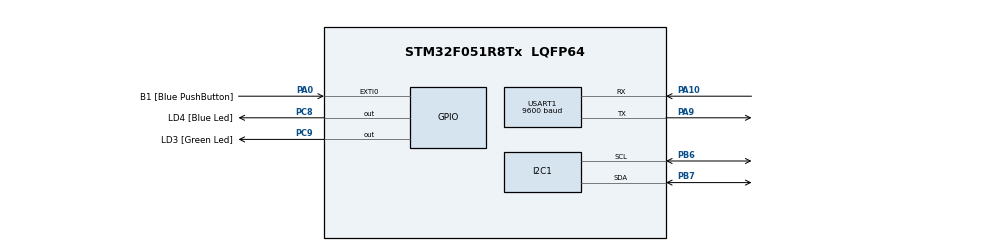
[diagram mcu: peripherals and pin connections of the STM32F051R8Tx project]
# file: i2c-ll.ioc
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I2C1.Timing=0x00201D2B
Mcu.Family=STM32F0
Mcu.Name=STM32F051R8Tx
Mcu.Package=LQFP64
PA0.GPIO_Label=B1 [Blue PushButton]
PA0.GPIO_ModeDefaultEXTI=GPIO_MODE_EVT_RISING
PA0.Signal=GPXTI0
PA10.Mode=Asynchronous
PA10.Signal=USART1_RX
PA13.GPIO_Label=SWDIO
PA13.Mode=Serial_Wire
PA13.Signal=SYS_SWDIO
PA14.GPIO_Label=SWCLK
PA14.Mode=Serial_Wire
PA14.Signal=SYS_SWCLK
PA9.Mode=Asynchronous
PA9.Signal=USART1_TX
PB6.Mode=I2C
PB6.Signal=I2C1_SCL
PB7.Mode=I2C
PB7.Signal=I2C1_SDA
PC8.GPIO_Label=LD4 [Blue Led]
PC8.Signal=GPIO_Output
PC9.GPIO_Label=LD3 [Green Led]
PC9.Signal=GPIO_Output
ProjectManager.HeapSize=0x200
ProjectManager.StackSize=0x400
ProjectManager.TargetToolchain=Makefile
RCC.AHBFreq_Value=48000000
RCC.APB1Freq_Value=48000000
RCC.APB1TimFreq_Value=48000000
RCC.HCLKFreq_Value=48000000
RCC.PLLMUL=RCC_PLL_MUL12
RCC.SYSCLKFreq_VALUE=48000000
RCC.SYSCLKSource=RCC_SYSCLKSOURCE_PLLCLK
USART1.BaudRate=9600
USART1.VirtualMode-Asynchronous=VM_ASYNC
board=STM32F0DISCOVERY

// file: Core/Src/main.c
/* USER CODE BEGIN Header */
/**
  ******************************************************************************
  * @file           : main.c
  * @brief          : Main program body
  ******************************************************************************
  * @attention
  *
  * Copyright (c) 2026 STMicroelectronics.
  * All rights reserved.
  *
  * This software is licensed under terms that can be found in the LICENSE file
  * in the root directory of this software component.
  * If no LICENSE file comes with this software, it is provided AS-IS.
  *
  ******************************************************************************
  */
/* USER CODE END Header */
#include "main.h"

/* USER CODE BEGIN Includes */
#include "bmp180_port.h"

/* USER CODE END Includes */

/* USER CODE BEGIN PV */
struct bmp180_t bmp180sensor;

/* USER CODE END PV */

void SystemClock_Config(void);
static void MX_GPIO_Init(void);
static void MX_I2C1_Init(void);
static void MX_USART1_UART_Init(void);

int main(void)
{

  /* MCU Configuration--------------------------------------------------------*/

  /* Reset of all peripherals, Initializes the Flash interface and the Systick. */
  LL_APB1_GRP2_EnableClock(LL_APB1_GRP2_PERIPH_SYSCFG);
  LL_APB1_GRP1_EnableClock(LL_APB1_GRP1_PERIPH_PWR);

  /* Configure the system clock */
  SystemClock_Config();

  /* Initialize all configured peripherals */
  MX_GPIO_Init();
  MX_I2C1_Init();
  MX_USART1_UART_Init();
  /* USER CODE BEGIN 2 */
  if (BMP180_PortInit(&bmp180sensor) != 0)
  {
    // init failed — check wiring/pull-ups/address
    while (1) { }
  }

  /* USER CODE END 2 */

  /* Infinite loop */
  while (1)
  {

  }
}

void SystemClock_Config(void)
{
  LL_FLASH_SetLatency(LL_FLASH_LATENCY_1);
  while(LL_FLASH_GetLatency() != LL_FLASH_LATENCY_1)
  {
  }
  LL_RCC_HSI_Enable();

   /* Wait till HSI is ready */
  while(LL_RCC_HSI_IsReady() != 1)
  {

  }
  LL_RCC_HSI_SetCalibTrimming(16);
  LL_RCC_PLL_ConfigDomain_SYS(LL_RCC_PLLSOURCE_HSI_DIV_2, LL_RCC_PLL_MUL_12);
  LL_RCC_PLL_Enable();

   /* Wait till PLL is ready */
  while(LL_RCC_PLL_IsReady() != 1)
  {

  }
  LL_RCC_SetAHBPrescaler(LL_RCC_SYSCLK_DIV_1);
  LL_RCC_SetAPB1Prescaler(LL_RCC_APB1_DIV_1);
  LL_RCC_SetSysClkSource(LL_RCC_SYS_CLKSOURCE_PLL);

   /* Wait till System clock is ready */
  while(LL_RCC_GetSysClkSource() != LL_RCC_SYS_CLKSOURCE_STATUS_PLL)
  {

  }
  LL_Init1msTick(48000000);
  LL_SetSystemCoreClock(48000000);
  LL_RCC_SetUSARTClockSource(LL_RCC_USART1_CLKSOURCE_PCLK1);
  LL_RCC_SetI2CClockSource(LL_RCC_I2C1_CLKSOURCE_HSI);
}

static void MX_I2C1_Init(void)
{

  LL_I2C_InitTypeDef I2C_InitStruct = {0};

  LL_GPIO_InitTypeDef GPIO_InitStruct = {0};

  LL_AHB1_GRP1_EnableClock(LL_AHB1_GRP1_PERIPH_GPIOB);
  /**I2C1 GPIO Configuration
  PB6   ------> I2C1_SCL
  PB7   ------> I2C1_SDA
  */
  GPIO_InitStruct.Pin = LL_GPIO_PIN_6;
  GPIO_InitStruct.Mode = LL_GPIO_MODE_ALTERNATE;
  GPIO_InitStruct.Speed = LL_GPIO_SPEED_FREQ_HIGH;
  GPIO_InitStruct.OutputType = LL_GPIO_OUTPUT_OPENDRAIN;
  GPIO_InitStruct.Pull = LL_GPIO_PULL_NO;
  GPIO_InitStruct.Alternate = LL_GPIO_AF_1;
  LL_GPIO_Init(GPIOB, &GPIO_InitStruct);

  GPIO_InitStruct.Pin = LL_GPIO_PIN_7;
  GPIO_InitStruct.Mode = LL_GPIO_MODE_ALTERNATE;
  GPIO_InitStruct.Speed = LL_GPIO_SPEED_FREQ_HIGH;
  GPIO_InitStruct.OutputType = LL_GPIO_OUTPUT_OPENDRAIN;
  GPIO_InitStruct.Pull = LL_GPIO_PULL_NO;
  GPIO_InitStruct.Alternate = LL_GPIO_AF_1;
  LL_GPIO_Init(GPIOB, &GPIO_InitStruct);

  /* Peripheral clock enable */
  LL_APB1_GRP1_EnableClock(LL_APB1_GRP1_PERIPH_I2C1);

  /** I2C Initialization
  */
  LL_I2C_DisableOwnAddress2(I2C1);
  LL_I2C_DisableGeneralCall(I2C1);
  LL_I2C_EnableClockStretching(I2C1);
  I2C_InitStruct.PeripheralMode = LL_I2C_MODE_I2C;
  I2C_InitStruct.Timing = 0x00201D2B;
  I2C_InitStruct.AnalogFilter = LL_I2C_ANALOGFILTER_ENABLE;
  I2C_InitStruct.DigitalFilter = 0;
  I2C_InitStruct.OwnAddress1 = 0;
  I2C_InitStruct.TypeAcknowledge = LL_I2C_ACK;
  I2C_InitStruct.OwnAddrSize = LL_I2C_OWNADDRESS1_7BIT;
  LL_I2C_Init(I2C1, &I2C_InitStruct);
  LL_I2C_EnableAutoEndMode(I2C1);
  LL_I2C_SetOwnAddress2(I2C1, 0, LL_I2C_OWNADDRESS2_NOMASK);

}

static void MX_USART1_UART_Init(void)
{

  LL_USART_InitTypeDef USART_InitStruct = {0};

  LL_GPIO_InitTypeDef GPIO_InitStruct = {0};

  /* Peripheral clock enable */
  LL_APB1_GRP2_EnableClock(LL_APB1_GRP2_PERIPH_USART1);

  LL_AHB1_GRP1_EnableClock(LL_AHB1_GRP1_PERIPH_GPIOA);
  /**USART1 GPIO Configuration
  PA9   ------> USART1_TX
  PA10   ------> USART1_RX
  */
  GPIO_InitStruct.Pin = LL_GPIO_PIN_9;
  GPIO_InitStruct.Mode = LL_GPIO_MODE_ALTERNATE;
  GPIO_InitStruct.Speed = LL_GPIO_SPEED_FREQ_HIGH;
  GPIO_InitStruct.OutputType = LL_GPIO_OUTPUT_PUSHPULL;
  GPIO_InitStruct.Pull = LL_GPIO_PULL_NO;
  GPIO_InitStruct.Alternate = LL_GPIO_AF_1;
  LL_GPIO_Init(GPIOA, &GPIO_InitStruct);

  GPIO_InitStruct.Pin = LL_GPIO_PIN_10;
  GPIO_InitStruct.Mode = LL_GPIO_MODE_ALTERNATE;
  GPIO_InitStruct.Speed = LL_GPIO_SPEED_FREQ_HIGH;
  GPIO_InitStruct.OutputType = LL_GPIO_OUTPUT_PUSHPULL;
  GPIO_InitStruct.Pull = LL_GPIO_PULL_NO;
  GPIO_InitStruct.Alternate = LL_GPIO_AF_1;
  LL_GPIO_Init(GPIOA, &GPIO_InitStruct);

  USART_InitStruct.BaudRate = 9600;
  USART_InitStruct.DataWidth = LL_USART_DATAWIDTH_8B;
  USART_InitStruct.StopBits = LL_USART_STOPBITS_1;
  USART_InitStruct.Parity = LL_USART_PARITY_NONE;
  USART_InitStruct.TransferDirection = LL_USART_DIRECTION_TX_RX;
  USART_InitStruct.HardwareFlowControl = LL_USART_HWCONTROL_NONE;
  USART_InitStruct.OverSampling = LL_USART_OVERSAMPLING_16;
  LL_USART_Init(USART1, &USART_InitStruct);
  LL_USART_DisableIT_CTS(USART1);
  LL_USART_ConfigAsyncMode(USART1);
  LL_USART_Enable(USART1);

}

static void MX_GPIO_Init(void)
{
  LL_EXTI_InitTypeDef EXTI_InitStruct = {0};
  LL_GPIO_InitTypeDef GPIO_InitStruct = {0};

  /* GPIO Ports Clock Enable */
  LL_AHB1_GRP1_EnableClock(LL_AHB1_GRP1_PERIPH_GPIOA);
  LL_AHB1_GRP1_EnableClock(LL_AHB1_GRP1_PERIPH_GPIOC);
  LL_AHB1_GRP1_EnableClock(LL_AHB1_GRP1_PERIPH_GPIOB);

  /**/
  LL_GPIO_ResetOutputPin(LD4_GPIO_Port, LD4_Pin);

  /**/
  LL_GPIO_ResetOutputPin(LD3_GPIO_Port, LD3_Pin);

  /**/
  LL_SYSCFG_SetEXTISource(LL_SYSCFG_EXTI_PORTA, LL_SYSCFG_EXTI_LINE0);

  /**/
  LL_GPIO_SetPinPull(B1_GPIO_Port, B1_Pin, LL_GPIO_PULL_NO);

  /**/
  LL_GPIO_SetPinMode(B1_GPIO_Port, B1_Pin, LL_GPIO_MODE_INPUT);

  /**/
  EXTI_InitStruct.Line_0_31 = LL_EXTI_LINE_0;
  EXTI_InitStruct.LineCommand = ENABLE;
  EXTI_InitStruct.Mode = LL_EXTI_MODE_EVENT;
  EXTI_InitStruct.Trigger = LL_EXTI_TRIGGER_RISING;
  LL_EXTI_Init(&EXTI_InitStruct);

  /**/
  GPIO_InitStruct.Pin = LD4_Pin;
  GPIO_InitStruct.Mode = LL_GPIO_MODE_OUTPUT;
  GPIO_InitStruct.Speed = LL_GPIO_SPEED_FREQ_LOW;
  GPIO_InitStruct.OutputType = LL_GPIO_OUTPUT_PUSHPULL;
  GPIO_InitStruct.Pull = LL_GPIO_PULL_NO;
  LL_GPIO_Init(LD4_GPIO_Port, &GPIO_InitStruct);

  /**/
  GPIO_InitStruct.Pin = LD3_Pin;
  GPIO_InitStruct.Mode = LL_GPIO_MODE_OUTPUT;
  GPIO_InitStruct.Speed = LL_GPIO_SPEED_FREQ_LOW;
  GPIO_InitStruct.OutputType = LL_GPIO_OUTPUT_PUSHPULL;
  GPIO_InitStruct.Pull = LL_GPIO_PULL_NO;
  LL_GPIO_Init(LD3_GPIO_Port, &GPIO_InitStruct);

}

void Error_Handler(void)
{
  __disable_irq();
  while (1)
  {
  }
}
